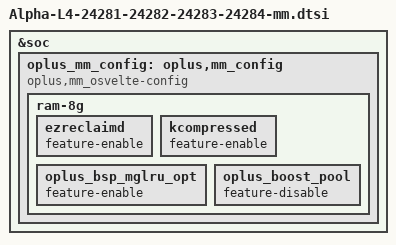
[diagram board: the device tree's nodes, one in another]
&soc {
  oplus_mm_config: oplus,mm_config {
    compatible = "oplus,mm_osvelte-config";
    ram-8g {
      ezreclaimd {
        feature-enable;
      };
      kcompressed {
        feature-enable;
      };
      oplus_bsp_mglru_opt {
        feature-enable;
      };
      oplus_boost_pool {
        feature-disable;
      };
    };
  };
};
